VERSION ""

NS_ :

BS_:

BU_:

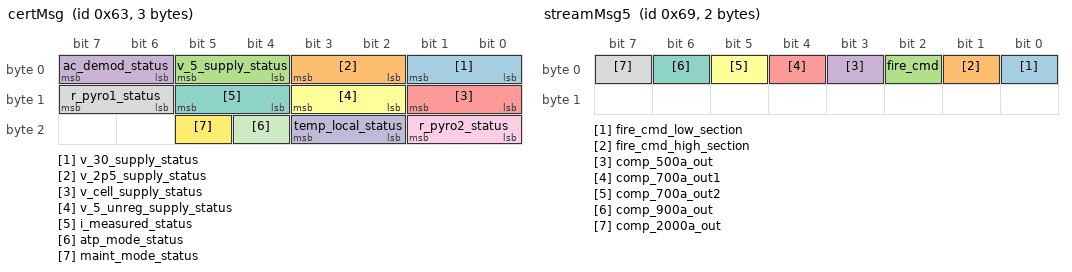
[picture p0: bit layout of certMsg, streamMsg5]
BO_ 99 certMsg: 3 Vector__XXX
 SG_ v_30_supply_status : 0|2@1+ (1,0) [-0|2] "" Vector__XXX
 SG_ v_2p5_supply_status : 2|2@1+ (1,0) [-0|2] "" Vector__XXX
 SG_ v_5_supply_status : 4|2@1+ (1,0) [-0|2] "" Vector__XXX
 SG_ ac_demod_status : 6|2@1+ (1,0) [-0|2] "" Vector__XXX
 SG_ v_cell_supply_status : 8|2@1+ (1,0) [-0|2] "" Vector__XXX
 SG_ v_5_unreg_supply_status : 10|2@1+ (1,0) [-0|2] "" Vector__XXX
 SG_ i_measured_status : 12|2@1+ (1,0) [-0|2] "" Vector__XXX
 SG_ r_pyro1_status : 14|2@1+ (1,0) [-0|2] "" Vector__XXX
 SG_ r_pyro2_status : 16|2@1+ (1,0) [-0|2] "" Vector__XXX
 SG_ temp_local_status : 18|2@1+ (1,0) [-0|2] "" Vector__XXX
 SG_ atp_mode_status : 20|1@1+ (1,0) [-0|2] "" Vector__XXX
 SG_ maint_mode_status:  21|1@1+ (1,0) [-0|2] "" Vector__XXX

BO_ 100 streamMsg0: 8 Vector__XXX
 SG_ v_30_supply : 0|32@1+ (1,0) [-9999|9999] "" Vector__XXX
 SG_ v_2p5_ref : 32|32@1+ (1,0) [-9999|9999] "" Vector__XXX

BO_ 101 streamMsg1: 8 Vector__XXX
 SG_ v_5_supply : 0|32@1+ (1,0) [-9999|9999] "" Vector__XXX
 SG_ i_measured : 32|32@1+ (1,0) [-9999|9999] "" Vector__XXX

BO_ 102 streamMsg2: 8 Vector__XXX
 SG_ r_pyro1 : 0|32@1+ (1,0) [-9999|9999] "" Vector__XXX
 SG_ r_pyro2 : 32|32@1+ (1,0) [-9999|9999] "" Vector__XXX

BO_ 103 streamMsg3: 8 Vector__XXX
 SG_ temp_local : 0|32@1+ (1,0) [-9999|9999] "" Vector__XXX
 SG_ unused : 32|32@1+ (1,0) [-9999|9999] "" Vector__XXX

BO_ 105 streamMsg5: 2 Vector__XXX
  SG_ fire_cmd_low_section : 0|1@1+ (1,0) [0|1] "" Vector__XXX
  SG_ fire_cmd_high_section : 1|1@1+ (1,0) [0|1] "" Vector__XXX
  SG_ fire_cmd : 2|1@1+ (1,0) [0|1] "" Vector__XXX
  SG_ comp_500a_out : 3|1@1+ (1,0) [0|1] "" Vector__XXX
  SG_ comp_700a_out1 : 4|1@1+ (1,0) [0|1] "" Vector__XXX
  SG_ comp_700a_out2 : 5|1@1+ (1,0) [0|1] "" Vector__XXX
  SG_ comp_900a_out : 6|1@1+ (1,0) [0|1] "" Vector__XXX
  SG_ comp_2000a_out : 7|1@1+ (1,0) [0|1] "" Vector__XXX

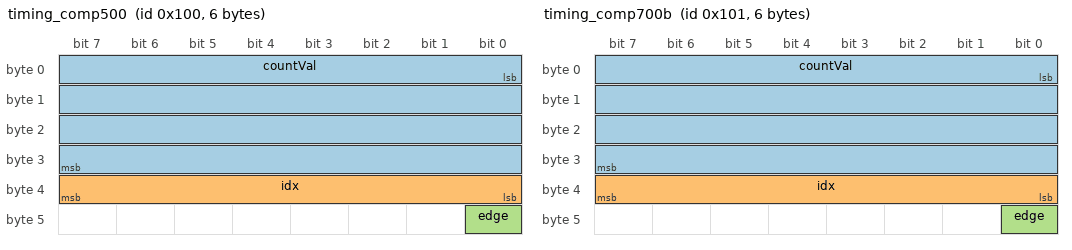
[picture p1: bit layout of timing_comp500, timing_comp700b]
BO_ 256 timing_comp500: 6 Vector__XXX
  SG_ countVal : 0|32@1+ (1,0) [0|4294967296] "microseconds" Vector__XXX
  SG_ idx : 32|8@1+ (1,0) [0|256] "" Vector__XXX
  SG_ edge : 40|1@1+ (1,0) [0|1] "" Vector__XXX

BO_ 257 timing_comp700b: 6 Vector__XXX
  SG_ countVal : 0|32@1+ (1,0) [0|4294967296] "microseconds" Vector__XXX
  SG_ idx : 32|8@1+ (1,0) [0|256] "" Vector__XXX
  SG_ edge : 40|1@1+ (1,0) [0|1] "" Vector__XXX

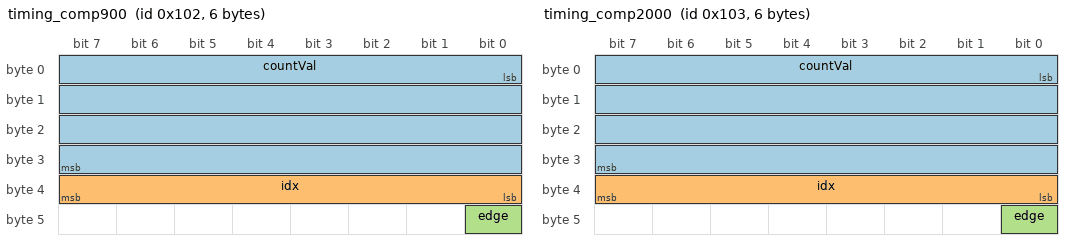
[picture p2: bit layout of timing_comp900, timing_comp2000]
BO_ 258 timing_comp900: 6 Vector__XXX
  SG_ countVal : 0|32@1+ (1,0) [0|4294967296] "microseconds" Vector__XXX
  SG_ idx : 32|8@1+ (1,0) [0|256] "" Vector__XXX
  SG_ edge : 40|1@1+ (1,0) [0|1] "" Vector__XXX

BO_ 259 timing_comp2000: 6 Vector__XXX
  SG_ countVal : 0|32@1+ (1,0) [0|4294967296] "microseconds" Vector__XXX
  SG_ idx : 32|8@1+ (1,0) [0|256] "" Vector__XXX
  SG_ edge : 40|1@1+ (1,0) [0|1] "" Vector__XXX

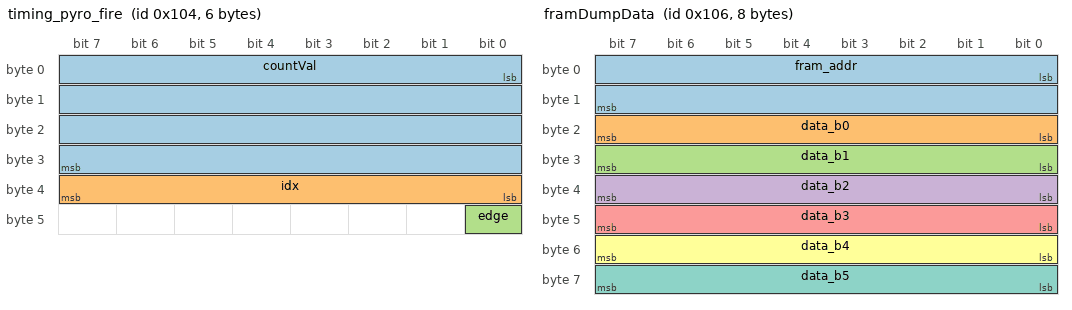
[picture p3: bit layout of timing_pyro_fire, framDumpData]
BO_ 260 timing_pyro_fire: 6 Vector__XXX
  SG_ countVal : 0|32@1+ (1,0) [0|4294967296] "microseconds" Vector__XXX
  SG_ idx : 32|8@1+ (1,0) [0|256] "" Vector__XXX
  SG_ edge : 40|1@1+ (1,0) [0|1] "" Vector__XXX

BO_ 261 i_trace: 1 Vector__XXX
  SG_ placeholder : 0|1@1+ (1,0) [0|1] "" Vector__XXX

BO_ 262 framDumpData: 8 Vector__XXX
  SG_ fram_addr : 0|16@1+ (1,0) [0|32767] "" Vector__XXX
  SG_ data_b0 : 16|8@1+ (1,0) [0|255] "" Vector__XXX
  SG_ data_b1 : 24|8@1+ (1,0) [0|255] "" Vector__XXX
  SG_ data_b2 : 32|8@1+ (1,0) [0|255] "" Vector__XXX
  SG_ data_b3 : 40|8@1+ (1,0) [0|255] "" Vector__XXX
  SG_ data_b4 : 48|8@1+ (1,0) [0|255] "" Vector__XXX
  SG_ data_b5 : 56|8@1+ (1,0) [0|255] "" Vector__XXX

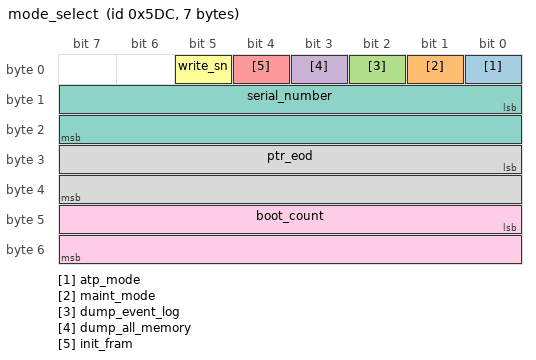
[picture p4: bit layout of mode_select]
BO_ 1500 mode_select: 7 Vector__XXX
  SG_ atp_mode : 0|1@1+ (1,0) [0|1] "" Vector__XXX
  SG_ maint_mode: 1|1@1+ (1,0) [0|1] "" Vector__XXX
  SG_ dump_event_log: 2|1@1+ (1,0) [0|1] "" Vector__XXX
  SG_ dump_all_memory: 3|1@1+ (1,0) [0|1] "" Vector__XXX
  SG_ init_fram: 4|1@1+ (1,0) [0|1] "" Vector__XXX
  SG_ write_sn: 5|1@1+ (1,0) [0|1] "" Vector__XXX
  SG_ serial_number: 8|16@1+ (1,0) [0|65535] "" Vector__XXX
  SG_ ptr_eod: 24|16@1+ (1,0) [0|65535] "" Vector__XXX
  SG_ boot_count: 40|16@1+ (1,0) [0|65535] "" Vector__XXX

BO_ 1501 maint_mode_pc: 4 Vector__XXX
  SG_ new_EOD_val : 0|16@1+ (1,0) [0|999999] "" Vector__XXX
  SG_ new_boot_count : 16|16@1+ (1,0) [0|999999] "" Vector__XXX

BO_ 1502 maint_mode_pyro: 4 Vector__XXX
  SG_ EOD_val : 0|16@1+ (1,0) [0|999999] "" Vector__XXX
  SG_ boot_count : 16|16@1+ (1,0) [0|999999] "" Vector__XXX

VAL_ 99 v_30_supply_status 0 "Low" 1 "Nominal" 3 "High" ;
VAL_ 99 v_2p5_supply_status 0 "Low" 1 "Nominal" 3 "High" ;
VAL_ 99 v_5_supply_status 0 "Low" 1 "Nominal" 3 "High" ;
VAL_ 99 ac_demod_status 0 "Low" 1 "Nominal" 3 "High" ;
VAL_ 99 v_cell_supply_status 0 "Low" 1 "Nominal" 3 "High" ;
VAL_ 99 v_5_unreg_supply_status 0 "Low" 1 "Nominal" 3 "High" ;
VAL_ 99 i_measured_status 0 "Low" 1 "Nominal" 3 "High" ;
VAL_ 99 r_pyro1_status 0 "Low" 1 "Nominal" 3 "High" ;
VAL_ 99 r_pyro2_status 0 "Low" 1 "Nominal" 3 "High" ;
VAL_ 99 temp_local_status 0 "Low" 1 "Nominal" 3 "High" ;

VAL_ 105 fire_cmd_low_section 0 "Low" 1 "High";
VAL_ 105 fire_cmd_high_section 0 "Low" 1 "High";
VAL_ 105 fire_cmd 0 "Low" 1 "High";
VAL_ 105 comp_500a_out 0 "Low" 1 "High";
VAL_ 105 comp_700a_out1 0 "Low" 1 "High";
VAL_ 105 comp_700a_out2 0 "Low" 1 "High";
VAL_ 105 comp_900a_out 0 "Low" 1 "High";
VAL_ 105 comp_2000a_out 0 "Low" 1 "High";

VAL_ 256 edge 0 "Falling" 1 "Rising";
VAL_ 257 edge 0 "Falling" 1 "Rising";
VAL_ 258 edge 0 "Falling" 1 "Rising";
VAL_ 259 edge 0 "Falling" 1 "Rising";
VAL_ 260 edge 0 "Falling" 1 "Rising";

SIG_VALTYPE_ 100 v_30_supply : 1;
SIG_VALTYPE_ 100 v_2p5_ref : 1;

SIG_VALTYPE_ 101 v_5_supply : 1;
SIG_VALTYPE_ 101 i_measured : 1;

SIG_VALTYPE_ 102 r_pyro1 : 1;
SIG_VALTYPE_ 102 r_pyro2 : 1;

SIG_VALTYPE_ 103 temp_local : 1;
SIG_VALTYPE_ 103 unused : 1;
